# STM32F303CBT6 register map
File version: 1.0
Registers are 32-bit, access not given, reset 0x0 unless marked. A register's access mark holds for its fields unless they carry their own. Offsets are from the block's base; [hi:lo] are bit positions; {n}, {i} and the like mark numbered series.

## CAN
Base 0x40006400
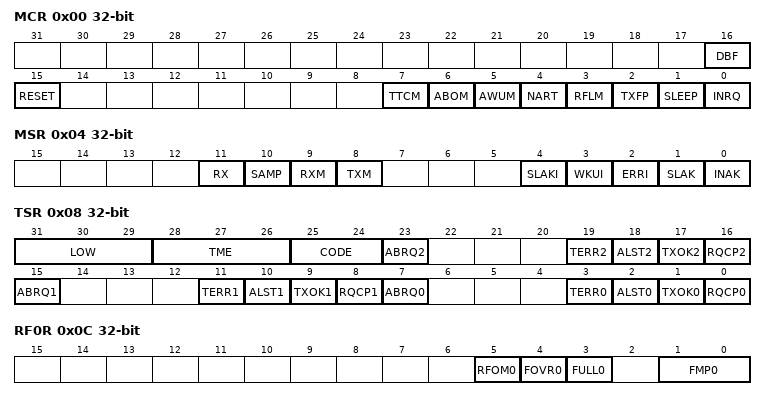
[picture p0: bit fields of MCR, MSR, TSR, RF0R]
0x00 MCR
  [16] DBF, [15] RESET, [7] TTCM, [6] ABOM, [5] AWUM, [4] NART, [3] RFLM, [2] TXFP, [1] SLEEP, [0] INRQ
0x04 MSR
  [11] RX, [10] SAMP, [9] RXM, [8] TXM, [4] SLAKI, [3] WKUI, [2] ERRI, [1] SLAK, [0] INAK
0x08 TSR
  [31:29] LOW, [28:26] TME, [25:24] CODE, [23] ABRQ2, [19] TERR2, [18] ALST2, [17] TXOK2, [16] RQCP2, [15] ABRQ1, [11] TERR1, [10] ALST1, [9] TXOK1, [8] RQCP1, [7] ABRQ0, [3] TERR0, [2] ALST0, [1] TXOK0, [0] RQCP0
0x0C RF0R
  [5] RFOM0, [4] FOVR0, [3] FULL0, [1:0] FMP0
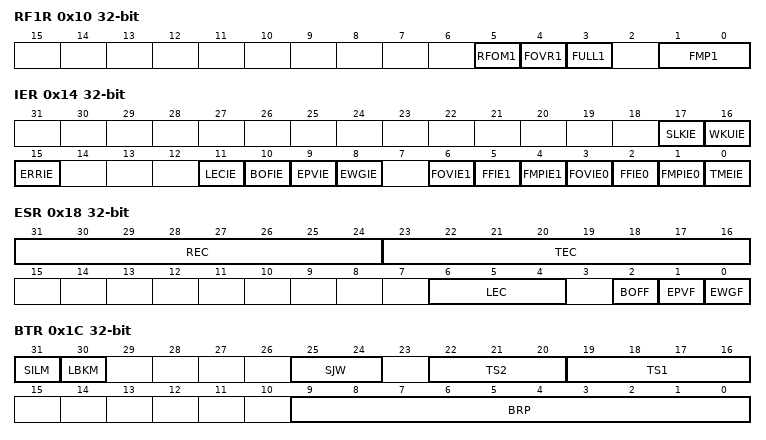
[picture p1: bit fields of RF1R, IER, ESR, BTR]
0x10 RF1R
  [5] RFOM1, [4] FOVR1, [3] FULL1, [1:0] FMP1
0x14 IER
  [17] SLKIE, [16] WKUIE, [15] ERRIE, [11] LECIE, [10] BOFIE, [9] EPVIE, [8] EWGIE, [6] FOVIE1, [5] FFIE1, [4] FMPIE1, [3] FOVIE0, [2] FFIE0, [1] FMPIE0, [0] TMEIE
0x18 ESR
  [31:24] REC, [23:16] TEC, [6:4] LEC, [2] BOFF, [1] EPVF, [0] EWGF
0x1C BTR
  [31] SILM, [30] LBKM, [25:24] SJW, [22:20] TS2, [19:16] TS1, [9:0] BRP
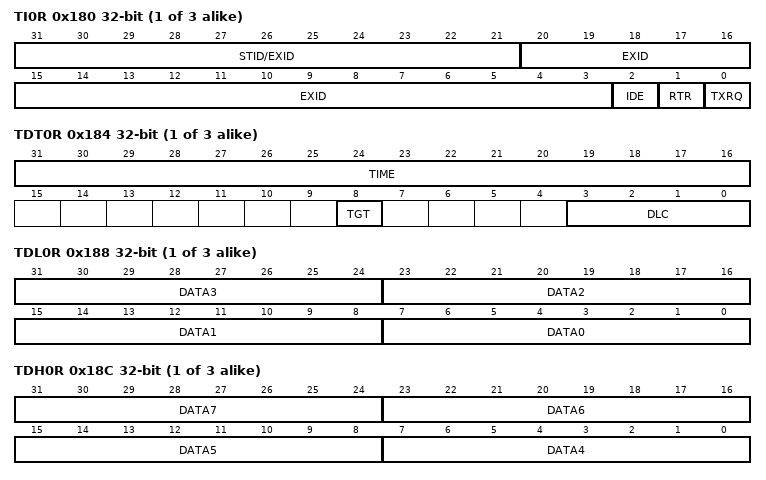
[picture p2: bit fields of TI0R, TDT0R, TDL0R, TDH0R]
{0x180+0x10*i} TI{i}R (i=0..2)
  [31:21] STID/EXID, [20:3] EXID, [2] IDE, [1] RTR, [0] TXRQ
{0x184+0x10*i} TDT{i}R (i=0..2)
  [31:16] TIME, [8] TGT, [3:0] DLC
{0x188+0x10*i} TDL{i}R (i=0..2)
  [8n+7:8n] DATA{n} (n=0..3)
{0x18C+0x10*i} TDH{i}R (i=0..2)
  [8n-25:8n-32] DATA{n} (n=4..7)
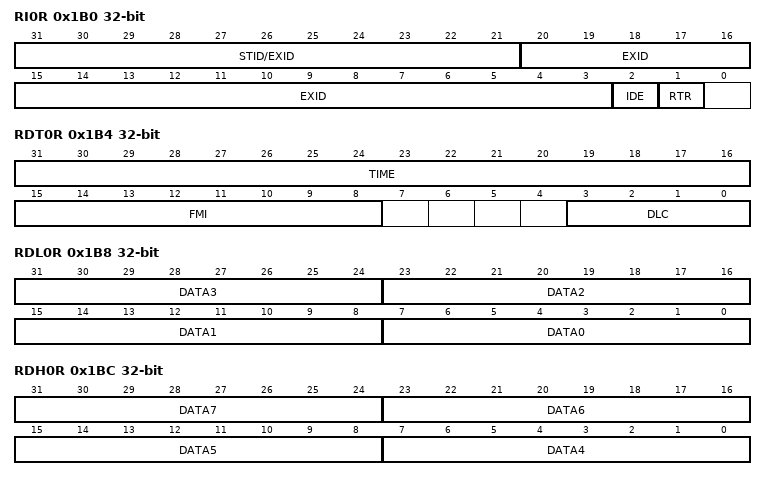
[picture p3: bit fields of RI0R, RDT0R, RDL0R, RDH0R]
0x1B0 RI0R
  [31:21] STID/EXID, [20:3] EXID, [2] IDE, [1] RTR
0x1B4 RDT0R
  [31:16] TIME, [15:8] FMI, [3:0] DLC
0x1B8 RDL0R
  [8n+7:8n] DATA{n} (n=0..3)
0x1BC RDH0R
  [8n-25:8n-32] DATA{n} (n=4..7)
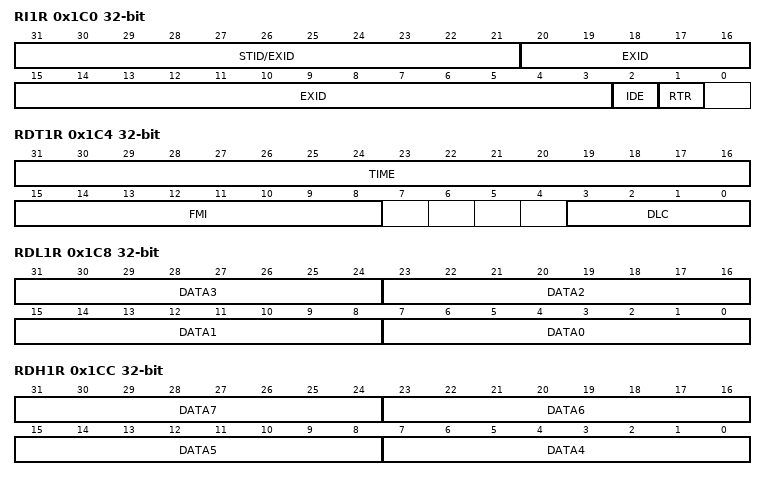
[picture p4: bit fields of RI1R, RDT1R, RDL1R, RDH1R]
0x1C0 RI1R
  [31:21] STID/EXID, [20:3] EXID, [2] IDE, [1] RTR
0x1C4 RDT1R
  [31:16] TIME, [15:8] FMI, [3:0] DLC
0x1C8 RDL1R
  [8n+7:8n] DATA{n} (n=0..3)
0x1CC RDH1R
  [8n-25:8n-32] DATA{n} (n=4..7)
0x200 FMR
  [0] FINIT
0x204 FM1R
  [13:0] FBM
0x20C FS1R
  [13:0] FSC
0x214 FFA1R
  [13:0] FFA
0x21C FA1R
  [13:0] FACT
{0x240+8i} F{i}R1 (i=0..27)
  [31:0] FB
{0x244+8i} F{i}R2 (i=0..27)
  [31:0] FB

## PWR
Base 0x40007000
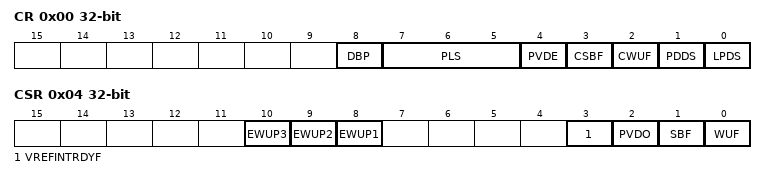
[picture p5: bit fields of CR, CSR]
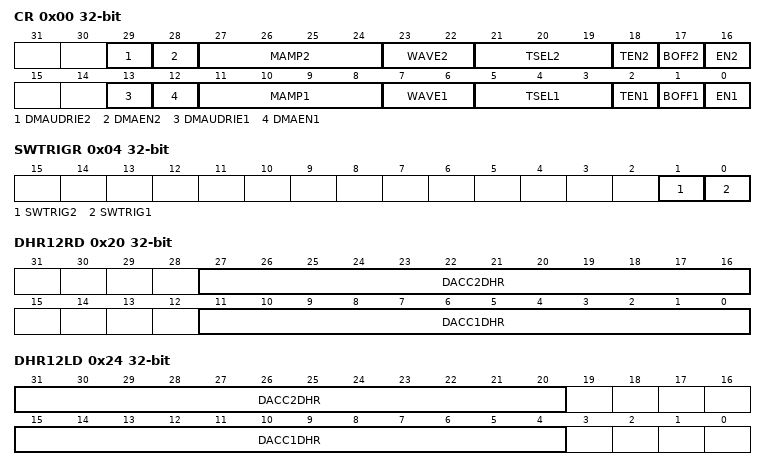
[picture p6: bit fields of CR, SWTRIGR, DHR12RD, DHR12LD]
0x00 CR
  [8] DBP, [7:5] PLS, [4] PVDE, [3] CSBF, [2] CWUF, [1] PDDS, [0] LPDS
0x04 CSR
  [10] EWUP3, [9] EWUP2, [8] EWUP1, [3] VREFINTRDYF, [2] PVDO, [1] SBF, [0] WUF

## DAC1
Base 0x40007400
0x00 CR
  [29] DMAUDRIE2, [28] DMAEN2, [27:24] MAMP2, [23:22] WAVE2, [21:19] TSEL2, [18] TEN2, [17] BOFF2, [16] EN2, [13] DMAUDRIE1, [12] DMAEN1, [11:8] MAMP1, [7:6] WAVE1, [5:3] TSEL1, [2] TEN1, [1] BOFF1, [0] EN1
0x04 SWTRIGR
  [1] SWTRIG2, [0] SWTRIG1
0x08 DHR12R1
  [11:0] DACC1DHR
0x0C DHR12L1
  [15:4] DACC1DHR
0x10 DHR8R1
  [7:0] DACC1DHR
0x14 DHR12R2
  [11:0] DACC2DHR
0x18 DHR12L2
  [15:4] DACC2DHR
0x1C DHR8R2
  [7:0] DACC2DHR
0x20 DHR12RD
  [27:16] DACC2DHR, [11:0] DACC1DHR
0x24 DHR12LD
  [31:20] DACC2DHR, [15:4] DACC1DHR
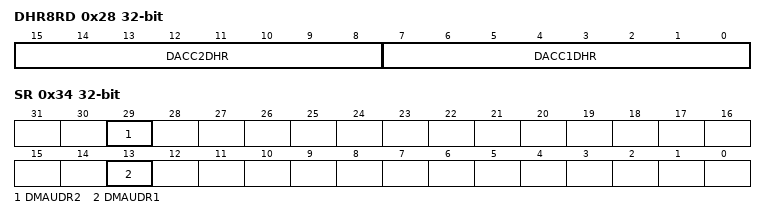
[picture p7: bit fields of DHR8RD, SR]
0x28 DHR8RD
  [15:8] DACC2DHR, [7:0] DACC1DHR
0x2C DOR1
  [11:0] DACC1DOR
0x30 DOR2
  [11:0] DACC2DOR
0x34 SR
  [29] DMAUDR2, [13] DMAUDR1

## OPAMP
Base 0x40010000
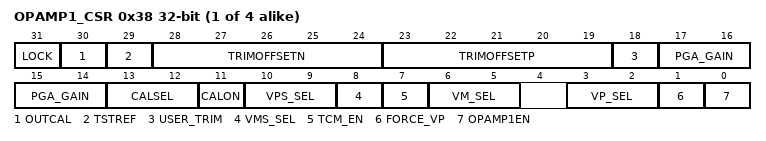
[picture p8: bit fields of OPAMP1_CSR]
{0x34+4i} OPAMP{i}_CSR (i=1..4)
  [31] LOCK, [30] OUTCAL, [29] TSTREF, [28:24] TRIMOFFSETN, [23:19] TRIMOFFSETP, [18] USER_TRIM, [17:14] PGA_GAIN, [13:12] CALSEL, [11] CALON, [10:9] VPS_SEL, [8] VMS_SEL, [7] TCM_EN, [6:5] VM_SEL, [3:2] VP_SEL, [1] FORCE_VP, [0] OPAMP{i}EN

## COMP
Base 0x40010000
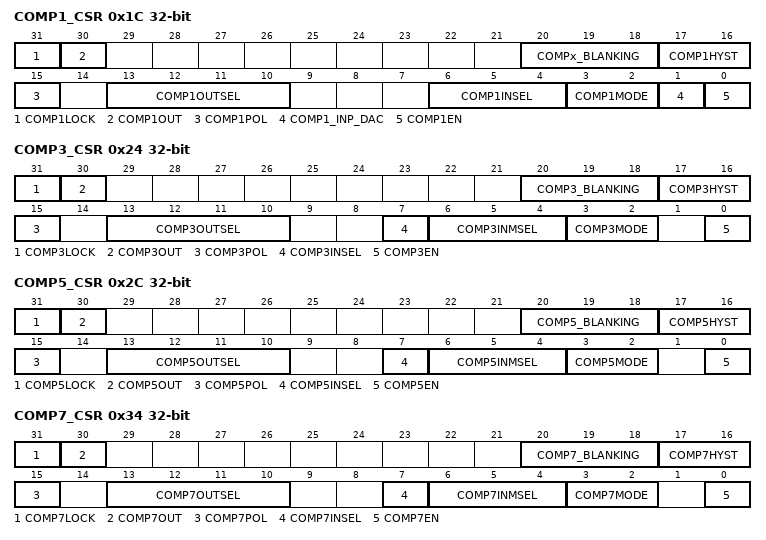
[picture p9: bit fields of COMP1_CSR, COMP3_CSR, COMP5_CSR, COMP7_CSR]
0x1C COMP1_CSR
  [31] COMP1LOCK, [30] COMP1OUT, [20:18] COMPx_BLANKING, [17:16] COMP1HYST, [15] COMP1POL, [13:10] COMP1OUTSEL, [6:4] COMP1INSEL, [3:2] COMP1MODE, [1] COMP1_INP_DAC, [0] COMP1EN
0x20 COMP2_CSR
  [31] COMP2LOCK, [30] COMP2OUT, [20:18] COMP2_BLANKING, [15] COMP2POL, [13:10] COMP2OUTSEL, [9] COMP2WINMODE, [7] COMP2INSEL, [22:4] COMP2INMSEL, [3:2] COMP2MODE, [1] COMP2_INP_DAC, [0] COMP2EN
0x24 COMP3_CSR
  [31] COMP3LOCK, [30] COMP3OUT, [20:18] COMP3_BLANKING, [17:16] COMP3HYST, [15] COMP3POL, [13:10] COMP3OUTSEL, [7] COMP3INSEL, [6:4] COMP3INMSEL, [3:2] COMP3MODE, [0] COMP3EN
0x28 COMP4_CSR
  [31] COMP4LOCK, [30] COMP4OUT, [20:18] COMP4_BLANKING, [15] COMP4POL, [13:10] COMP4OUTSEL, [9] COMP4WINMODE, [7] COMP4INSEL, [22:4] COMP4INMSEL, [3:2] COMP4MODE, [0] COMP4EN
0x2C COMP5_CSR
  [31] COMP5LOCK, [30] COMP5OUT, [20:18] COMP5_BLANKING, [17:16] COMP5HYST, [15] COMP5POL, [13:10] COMP5OUTSEL, [7] COMP5INSEL, [6:4] COMP5INMSEL, [3:2] COMP5MODE, [0] COMP5EN
0x30 COMP6_CSR
  [31] COMP6LOCK, [30] COMP6OUT, [20:18] COMP6_BLANKING, [15] COMP6POL, [13:10] COMP6OUTSEL, [9] COMP6WINMODE, [7] COMP6INSEL, [22:4] COMP6INMSEL, [3:2] COMP6MODE, [0] COMP6EN
0x34 COMP7_CSR
  [31] COMP7LOCK, [30] COMP7OUT, [20:18] COMP7_BLANKING, [17:16] COMP7HYST, [15] COMP7POL, [13:10] COMP7OUTSEL, [7] COMP7INSEL, [6:4] COMP7INMSEL, [3:2] COMP7MODE, [0] COMP7EN
